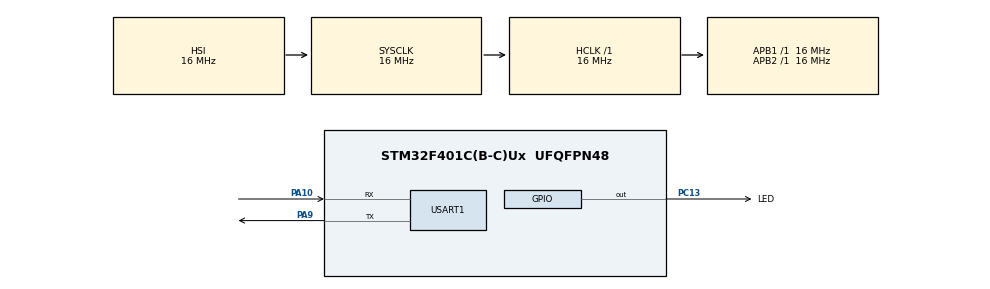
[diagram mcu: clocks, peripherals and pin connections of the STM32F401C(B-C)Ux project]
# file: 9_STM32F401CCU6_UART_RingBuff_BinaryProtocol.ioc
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Mcu.Family=STM32F4
Mcu.Name=STM32F401C(B-C)Ux
Mcu.Package=UFQFPN48
NVIC.PriorityGroup=NVIC_PRIORITYGROUP_4
NVIC.USART1_IRQn=true\:0\:0\:false\:false\:true\:true\:true\:true
PA10.Mode=Asynchronous
PA10.Signal=USART1_RX
PA13.Mode=Serial_Wire
PA13.Signal=SYS_JTMS-SWDIO
PA14.Mode=Serial_Wire
PA14.Signal=SYS_JTCK-SWCLK
PA9.Mode=Asynchronous
PA9.Signal=USART1_TX
PC13-ANTI_TAMP.GPIO_Label=LED
PC13-ANTI_TAMP.Signal=GPIO_Output
PC14-OSC32_IN.Mode=LSE-External-Oscillator
PC14-OSC32_IN.Signal=RCC_OSC32_IN
PC15-OSC32_OUT.Mode=LSE-External-Oscillator
PC15-OSC32_OUT.Signal=RCC_OSC32_OUT
PH0\ -\ OSC_IN.Mode=HSE-External-Oscillator
PH0\ -\ OSC_IN.Signal=RCC_OSC_IN
PH1\ -\ OSC_OUT.Mode=HSE-External-Oscillator
PH1\ -\ OSC_OUT.Signal=RCC_OSC_OUT
ProjectManager.HeapSize=0x200
ProjectManager.StackSize=0x400
ProjectManager.TargetToolchain=STM32CubeIDE
RCC.AHBFreq_Value=16000000
RCC.APB1Freq_Value=16000000
RCC.APB2Freq_Value=16000000
RCC.CortexFreq_Value=16000000
RCC.HSE_VALUE=25000000
RCC.HSI_VALUE=16000000
RCC.SYSCLKFreq_VALUE=16000000
RCC.VCOOutputFreq_Value=192000000
USART1.VirtualMode=VM_ASYNC
board=custom

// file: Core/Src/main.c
/* USER CODE BEGIN Header */
/**
  ******************************************************************************
  * @file           : main.c
  * @brief          : Main program body
  ******************************************************************************
  * @attention
  *
  * Copyright (c) 2026 STMicroelectronics.
  * All rights reserved.
  *
  * This software is licensed under terms that can be found in the LICENSE file
  * in the root directory of this software component.
  * If no LICENSE file comes with this software, it is provided AS-IS.
  *
  ******************************************************************************
  */
/* USER CODE END Header */
#include "main.h"

/* USER CODE BEGIN Includes */
#include "stdbool.h"
#include "stdio.h"
#include "string.h"
#include "stdbool.h"

#include "ring_buffer.h"
#include <api_command.h>
#include "crc8.h"
#include "protocol_parser.h"
#include "protocol.h"
#include <api_command.h>
#include "led.h"

//#include "stdbool.h"
/* USER CODE END Includes */

/* USER CODE BEGIN PD */
#define UART_RX_BUFFER_SIZE 128
static uint8_t uart_rx_storage[UART_RX_BUFFER_SIZE];
ring_buffer_t uart_rx_rb;

uint8_t uart_rx_byte;		// One byte for receive data

uint8_t byte = 0;	 // for tests

protocol_parser_t protocol_parser;
protocol_packed_t received_packet;

/* USER CODE END PD */

UART_HandleTypeDef huart1;

void SystemClock_Config(void);
static void MX_GPIO_Init(void);
static void MX_USART1_UART_Init(void);

/* USER CODE BEGIN 0 */
//void led_on_off(bool state)
//{
//	if(state == false)
//	{
//		HAL_GPIO_WritePin(GPIOC, GPIO_PIN_13, GPIO_PIN_SET);
//	}
//	else
//	{
//		HAL_GPIO_WritePin(GPIOC, GPIO_PIN_13, GPIO_PIN_RESET);
//	}
//}

/*
 *  Debug function
 */
void test_calculate_crc(void)
{
	const char msg[] = "CALCULATE CRC...\r\n";
	HAL_UART_Transmit(&huart1,(uint8_t*) msg, sizeof(msg)-1, HAL_MAX_DELAY);

	uint8_t test_crc[7] = {0xAA, 0x55, 0x03, 0x01, 0x19, 0x32, 0x48};
	uint8_t length_of_crc = length_of_crc = sizeof(test_crc)/sizeof(test_crc[0]);
	uint8_t crc =  crc8_calculate(test_crc, length_of_crc);
}

/* USER CODE END 0 */

int main(void)
{

  /* MCU Configuration--------------------------------------------------------*/

  /* Reset of all peripherals, Initializes the Flash interface and the Systick. */
  HAL_Init();

  /* Configure the system clock */
  SystemClock_Config();

  /* Initialize all configured peripherals */
  MX_GPIO_Init();
  MX_USART1_UART_Init();
  /* USER CODE BEGIN 2 */

  //test_calculate_crc();

  rb_init(&uart_rx_rb, uart_rx_storage, UART_RX_BUFFER_SIZE);
  protocol_parser_init(&protocol_parser);

  HAL_UART_Receive_IT(&huart1, &uart_rx_byte, 1);		// Enable receive one bite
  /* USER CODE END 2 */

  /* Infinite loop */
  /* USER CODE BEGIN WHILE */
  while (1)
  {

//	  led_on_off(true);
//	  HAL_Delay(100);
//	  led_on_off(false);
//	  HAL_Delay(900);

//	  if(rb_pop(&uart_rx_rb, &byte))
//	  {
//		  char str[10];
//		  sprintf(str, "%02X ", byte);
//		  HAL_UART_Transmit(&huart1, (uint8_t *)str, strlen(str), HAL_MAX_DELAY);
//	  }

	  if(rb_pop(&uart_rx_rb, &byte))
	  {
		  if(protocol_parser_process_byte(&protocol_parser, byte, &received_packet))
		  {
			  procces_packed(&received_packet);
//			  const char msg[] = "PACKED OK";
//			  HAL_UART_Transmit(&huart1,(uint8_t*) msg, sizeof(msg)-1, HAL_MAX_DELAY);
			  uint8_t test = 0;
		  }
	  }

    /* USER CODE END WHILE */

  }
}

void SystemClock_Config(void)
{
  RCC_OscInitTypeDef RCC_OscInitStruct = {0};
  RCC_ClkInitTypeDef RCC_ClkInitStruct = {0};

  /** Configure the main internal regulator output voltage
  */
  __HAL_RCC_PWR_CLK_ENABLE();
  __HAL_PWR_VOLTAGESCALING_CONFIG(PWR_REGULATOR_VOLTAGE_SCALE2);

  /** Initializes the RCC Oscillators according to the specified parameters
  * in the RCC_OscInitTypeDef structure.
  */
  RCC_OscInitStruct.OscillatorType = RCC_OSCILLATORTYPE_HSI;
  RCC_OscInitStruct.HSIState = RCC_HSI_ON;
  RCC_OscInitStruct.HSICalibrationValue = RCC_HSICALIBRATION_DEFAULT;
  RCC_OscInitStruct.PLL.PLLState = RCC_PLL_NONE;
  if (HAL_RCC_OscConfig(&RCC_OscInitStruct) != HAL_OK)
  {
    Error_Handler();
  }

  /** Initializes the CPU, AHB and APB buses clocks
  */
  RCC_ClkInitStruct.ClockType = RCC_CLOCKTYPE_HCLK|RCC_CLOCKTYPE_SYSCLK
                              |RCC_CLOCKTYPE_PCLK1|RCC_CLOCKTYPE_PCLK2;
  RCC_ClkInitStruct.SYSCLKSource = RCC_SYSCLKSOURCE_HSI;
  RCC_ClkInitStruct.AHBCLKDivider = RCC_SYSCLK_DIV1;
  RCC_ClkInitStruct.APB1CLKDivider = RCC_HCLK_DIV1;
  RCC_ClkInitStruct.APB2CLKDivider = RCC_HCLK_DIV1;

  if (HAL_RCC_ClockConfig(&RCC_ClkInitStruct, FLASH_LATENCY_0) != HAL_OK)
  {
    Error_Handler();
  }
}

static void MX_USART1_UART_Init(void)
{

  huart1.Instance = USART1;
  huart1.Init.BaudRate = 115200;
  huart1.Init.WordLength = UART_WORDLENGTH_8B;
  huart1.Init.StopBits = UART_STOPBITS_1;
  huart1.Init.Parity = UART_PARITY_NONE;
  huart1.Init.Mode = UART_MODE_TX_RX;
  huart1.Init.HwFlowCtl = UART_HWCONTROL_NONE;
  huart1.Init.OverSampling = UART_OVERSAMPLING_16;
  if (HAL_UART_Init(&huart1) != HAL_OK)
  {
    Error_Handler();
  }

}

static void MX_GPIO_Init(void)
{
  GPIO_InitTypeDef GPIO_InitStruct = {0};

  /* GPIO Ports Clock Enable */
  __HAL_RCC_GPIOC_CLK_ENABLE();
  __HAL_RCC_GPIOH_CLK_ENABLE();
  __HAL_RCC_GPIOA_CLK_ENABLE();

  /*Configure GPIO pin Output Level */
  HAL_GPIO_WritePin(LED_GPIO_Port, LED_Pin, GPIO_PIN_RESET);

  /*Configure GPIO pin : LED_Pin */
  GPIO_InitStruct.Pin = LED_Pin;
  GPIO_InitStruct.Mode = GPIO_MODE_OUTPUT_PP;
  GPIO_InitStruct.Pull = GPIO_NOPULL;
  GPIO_InitStruct.Speed = GPIO_SPEED_FREQ_LOW;
  HAL_GPIO_Init(LED_GPIO_Port, &GPIO_InitStruct);

}

/* USER CODE BEGIN 4 */
void HAL_UART_RxCpltCallback(UART_HandleTypeDef *huart)
{
	if(huart->Instance == USART1)
	{
		rb_push(&uart_rx_rb, uart_rx_byte);
		HAL_UART_Receive_IT(&huart1, &uart_rx_byte, 1);		// Enable receive one bite
	}

}

/* USER CODE END 4 */

void Error_Handler(void)
{
  __disable_irq();
  while (1)
  {
  }
}
